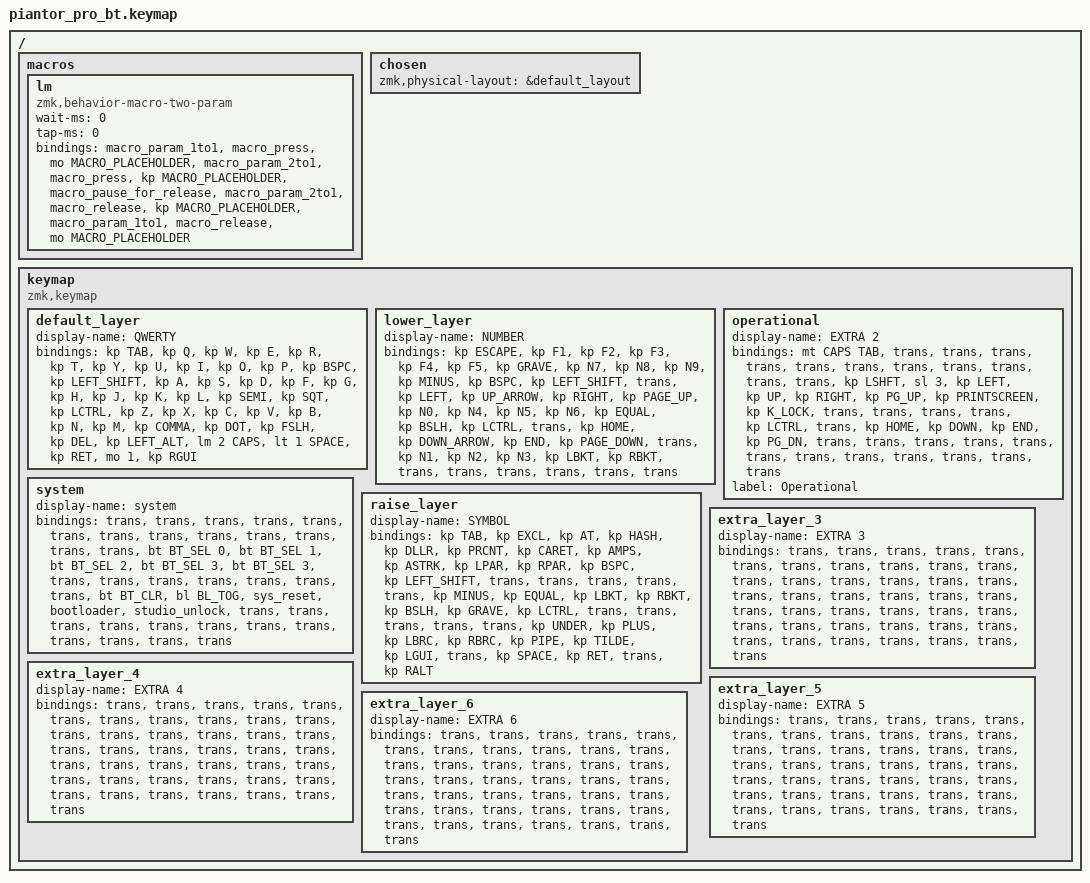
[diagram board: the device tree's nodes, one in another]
/*
 * Copyright (c) 2020 The ZMK Contributors
 *
 * SPDX-License-Identifier: MIT
 */

#include <behaviors.dtsi>
#include <dt-bindings/zmk/backlight.h>
#include <dt-bindings/zmk/bt.h>
#include <dt-bindings/zmk/keys.h>

/ {
    macros {
        /**
     * Temporarily switches to a layer (`&mo`) while a modifier is held.
     * Analogous to QMK's `LM()`, using a parameterized macro.
     *
     * Params:
     *  1. Layer to switch to
     *  2. Modifier to press while layer is active
     *
     * Example:
     *  `&lm NUM_LAYER LSHIFT`
     */

        lm: lm {
            compatible = "zmk,behavior-macro-two-param";
            wait-ms = <0>;
            tap-ms = <0>;
            #binding-cells = <2>;
            bindings =
                <&macro_param_1to1>,
                <&macro_press>,
                <&mo MACRO_PLACEHOLDER &macro_param_2to1>,
                <&macro_press>,
                <&kp MACRO_PLACEHOLDER>,
                <&macro_pause_for_release>,
                <&macro_param_2to1>,
                <&macro_release>,
                <&kp MACRO_PLACEHOLDER &macro_param_1to1>,
                <&macro_release>,
                <&mo MACRO_PLACEHOLDER>;
        };
    };
};

/ {
    chosen { zmk,physical-layout = &default_layout; };
};

/ {
    keymap {
        compatible = "zmk,keymap";

        default_layer {
            display-name = "QWERTY";

            // --------------------------------------------------------------------------------
            // |  TAB |  Q  |  W  |  E  |  R  |  T  |  Y  |  U   |  I  |  O  |  P  | BSPC |
            // | CTRL |  A  |  S  |  D  |  F  |  G  |  H  |  J   |  K  |  L  |  ;  |  '   |
            // | SHFT |  Z  |  X  |  C  |  V  |  B  |  N  |  M   |  ,  |  .  |  /  | ESC  |
            //                    | GUI | LWR | SPC | ENT | RSE  | ALT |

            bindings = <
&kp TAB  &kp Q  &kp W  &kp E  &kp R  &kp T  &kp Y  &kp U  &kp I  &kp O  &kp P  &kp BSPC  &kp LEFT_SHIFT  &kp A  &kp S  &kp D  &kp F  &kp G  &kp H  &kp J  &kp K  &kp L  &kp SEMI  &kp SQT  &kp LCTRL  &kp Z  &kp X  &kp C  &kp V  &kp B  &kp N  &kp M  &kp COMMA  &kp DOT  &kp FSLH  &kp DEL  &kp LEFT_ALT  &lm 2 CAPS  &lt 1 SPACE  &kp RET  &mo 1  &kp RGUI
            >;
        };

        lower_layer {
            display-name = "NUMBER";

            // -----------------------------------------------------------------------------------------
            // |  TAB |  1  |  2  |  3  |  4  |  5    |  6  |  7  |  8  |  9  |  0  | BSPC |
            // | CTRL | BT1 | BT2 | BT3 | BT4 | BT5   | LFT | DWN |  UP | RGT |     |      |
            // | SHFT | BTCR| RGB | RST | BOOT| Unlock|     |     |     |     |     |      |
            //                    | GUI |     | SPC   | ENT |     | ALT |

            bindings = <
&kp ESCAPE  &kp F1  &kp F2  &kp F3  &kp F4  &kp F5  &kp GRAVE  &kp N7  &kp N8  &kp N9  &kp MINUS  &kp BSPC  &kp LEFT_SHIFT  &trans  &kp LEFT  &kp UP_ARROW  &kp RIGHT  &kp PAGE_UP  &kp N0  &kp N4  &kp N5  &kp N6  &kp EQUAL  &kp BSLH  &kp LCTRL  &trans  &kp HOME  &kp DOWN_ARROW  &kp END  &kp PAGE_DOWN  &trans  &kp N1  &kp N2  &kp N3  &kp LBKT  &kp RBKT  &trans  &trans  &trans  &trans  &trans  &trans
            >;
        };

        operational {
            display-name = "EXTRA 2";
            bindings = <
&mt CAPS TAB  &trans  &trans  &trans  &trans  &trans  &trans  &trans  &trans  &trans  &trans  &trans  &kp LSHFT  &sl 3  &kp LEFT  &kp UP  &kp RIGHT  &kp PG_UP  &kp PRINTSCREEN  &kp K_LOCK  &trans  &trans  &trans  &trans  &kp LCTRL  &trans  &kp HOME  &kp DOWN  &kp END  &kp PG_DN  &trans  &trans  &trans  &trans  &trans  &trans  &trans  &trans  &trans  &trans  &trans  &trans
            >;

            label = "Operational";
        };

        system {
            display-name = "system";
            bindings = <
&trans  &trans  &trans  &trans  &trans  &trans  &trans  &trans  &trans  &trans  &trans  &trans  &trans  &bt BT_SEL 0  &bt BT_SEL 1  &bt BT_SEL 2  &bt BT_SEL 3  &bt BT_SEL 3  &trans  &trans  &trans  &trans  &trans  &trans  &trans  &bt BT_CLR  &bl BL_TOG  &sys_reset  &bootloader  &studio_unlock  &trans  &trans  &trans  &trans  &trans  &trans  &trans  &trans  &trans  &trans  &trans  &trans
            >;
        };

        raise_layer {
            display-name = "SYMBOL";

            // -----------------------------------------------------------------------------------------
            // |  TAB |  !  |  @  |  #  |  $  |  %  |  ^  |  &  |  *  |  (  |  )  | BSPC |
            // | CTRL |     |     |     |     |     |  -  |  =  |  [  |  ]  |  \  |  `   |
            // | SHFT |     |     |     |     |     |  _  |  +  |  {  |  }  | "|" |  ~   |
            //                    | GUI |     | SPC | ENT |     | ALT |

            bindings = <
&kp TAB  &kp EXCL  &kp AT  &kp HASH  &kp DLLR  &kp PRCNT  &kp CARET  &kp AMPS  &kp ASTRK  &kp LPAR  &kp RPAR  &kp BSPC  &kp LEFT_SHIFT  &trans  &trans  &trans  &trans  &trans  &kp MINUS  &kp EQUAL  &kp LBKT  &kp RBKT  &kp BSLH  &kp GRAVE  &kp LCTRL  &trans  &trans  &trans  &trans  &trans  &kp UNDER  &kp PLUS  &kp LBRC  &kp RBRC  &kp PIPE  &kp TILDE  &kp LGUI  &trans  &kp SPACE  &kp RET  &trans  &kp RALT
            >;
        };

        extra_layer_3 {
            display-name = "EXTRA 3";
            bindings = <
&trans  &trans  &trans  &trans  &trans  &trans  &trans  &trans  &trans  &trans  &trans  &trans  &trans  &trans  &trans  &trans  &trans  &trans  &trans  &trans  &trans  &trans  &trans  &trans  &trans  &trans  &trans  &trans  &trans  &trans  &trans  &trans  &trans  &trans  &trans  &trans  &trans  &trans  &trans  &trans  &trans  &trans
            >;
        };

        extra_layer_4 {
            display-name = "EXTRA 4";
            bindings = <
&trans  &trans  &trans  &trans  &trans  &trans  &trans  &trans  &trans  &trans  &trans  &trans  &trans  &trans  &trans  &trans  &trans  &trans  &trans  &trans  &trans  &trans  &trans  &trans  &trans  &trans  &trans  &trans  &trans  &trans  &trans  &trans  &trans  &trans  &trans  &trans  &trans  &trans  &trans  &trans  &trans  &trans
            >;
        };

        extra_layer_5 {
            display-name = "EXTRA 5";
            bindings = <
&trans  &trans  &trans  &trans  &trans  &trans  &trans  &trans  &trans  &trans  &trans  &trans  &trans  &trans  &trans  &trans  &trans  &trans  &trans  &trans  &trans  &trans  &trans  &trans  &trans  &trans  &trans  &trans  &trans  &trans  &trans  &trans  &trans  &trans  &trans  &trans  &trans  &trans  &trans  &trans  &trans  &trans
            >;
        };

        extra_layer_6 {
            display-name = "EXTRA 6";
            bindings = <
&trans  &trans  &trans  &trans  &trans  &trans  &trans  &trans  &trans  &trans  &trans  &trans  &trans  &trans  &trans  &trans  &trans  &trans  &trans  &trans  &trans  &trans  &trans  &trans  &trans  &trans  &trans  &trans  &trans  &trans  &trans  &trans  &trans  &trans  &trans  &trans  &trans  &trans  &trans  &trans  &trans  &trans
            >;
        };
    };
};
